# PIC32MK1024GPK100 device description
Architecture: MIPS; Family: PIC32MK; Series: PIC32MK
Registers are 32-bit, read-write, no defined reset value unless marked. A register's access mark holds for its fields unless they carry their own. Offsets are from the block's base; [hi:lo] are bit positions; {n}, {i} and the like mark numbered series.

## CDAC
Instances: CDAC 0x1f820000 in periph_pb2_std
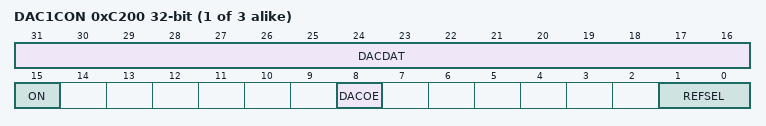
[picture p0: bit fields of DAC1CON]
{0xC000+0x200*i} DAC{i}CON (i=1..3) — CDAC Control Register
  [31:16] DACDAT
  [15] ON — CDAC Enable bit
    1=The CDAC is enabled; 0=The CDAC is disabled
  [8] DACOE — CDAC Output Buffer Enable bit
    1=Output is enabled; CDAC voltage is connected to the pin; 0=Output is disabled; drive to pin is floating
  [1:0] REFSEL — Reference Source Select bits
    3=Positive reference voltage = AVDD; 0=No reference selected (no reference current consumption)

## CTMU
Instances: CTMU 0x1f82d000 in periph_pb2_std
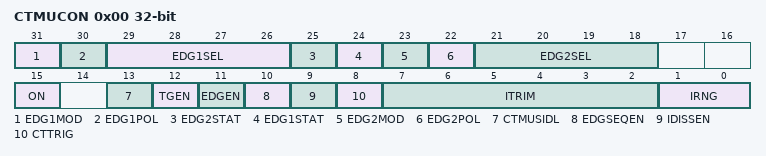
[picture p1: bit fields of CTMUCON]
0x00 CTMUCON — CTMU Control Register
  [31] EDG1MOD — Edge1 Edge Sampling Select bit
    1=Input is edge-sensitive; 0=Input is level-sensitive
  [30] EDG1POL — Edge 1 Polarity Select bit
    1=Edge1 programmed for a high level response; 0=Edge1 programmed for a low level response
  [29:26] EDG1SEL — Edge 1 Source Select bits
    15=C5OUT pin is selected; 14=C4OUT pin is selected; 13=C1OUT pin is selected; {v}=IC{v-6} Capture Event is selected (v=7..12); 6=OC4 Capture Event is selected; 5=OC3 Capture Event is selected; 4=OC2 Capture Event is selected; 3=CTED1 pin is selected; 2=CTED2 pin is selected; 1=OC1 Compare Event is selected; 0=Timer1 Event is selected
  [25] EDG2STAT — Edge2 Status bit
    1=Edge2 event has occurred; 0=Edge2 event has not occurred
  [24] EDG1STAT — Edge1 Status bit
    1=Edge1 event has occurred; 0=Edge1 event has not occurred
  [23] EDG2MOD — Edge2 Edge Sampling Select bit
    1=Input is edge-sensitive; 0=Input is level-sensitive
  [22] EDG2POL — Edge 2 Polarity Select bit
    1=Edge2 programmed for a high level response; 0=Edge2 programmed for a low level response
  [21:18] EDG2SEL — Edge 2 Source Select bits
    15=C5OUT Capture Event is selected; 14=C4OUT pin is selected; 13=C1OUT pin is selected; 12=PBCLK2 is selected; {v}=IC{v-6} Capture Event is selected (v=7..11); 6=OC4 Capture Event is selected; 5=OC3 Capture Event is selected; 4=OC2 Capture Event is selected; 3=CTED1 pin is selected; 2=CTED2 pin is selected; 1=OC1 Compare Event is selected; 0=Timer1 Event is selected
  [15] ON — ON Enable bit
    1=Module is enabled; 0=Module is disabled
  [13] CTMUSIDL — Stop in Idle Mode bit
    1=Discontinue module operation when device enters Idle mode; 0=Continue module operation in Idle mode
  [12] TGEN — Time Generation Enable bit
    1=Enables edge delay generation; 0=Disables edge delay generation
  [11] EDGEN — Edge Enable bit
    1=Edges are not blocked; 0=Edges are blocked
  [10] EDGSEQEN — Edge Sequence Enable bit
    1=Edge1 must occur before Edge2 can occur; 0=No edge sequence is needed
  [9] IDISSEN — Analog Current Source Control bit
    1=Analog current source output is grounded; 0=Analog current source output is not grounded
  [8] CTTRIG — Trigger Control bit
    1=Trigger output is enabled; 0=Trigger output is disabled
  [7:2] ITRIM — Current Source Trim bits
    31=Maximum positive change from nominal current; 1=Minimum positive change from nominal current; 0=Nominal current output specified by IRNG; 63=Minimum negative change from nominal current; 33=Maximum negative change from nominal current
  [1:0] IRNG — Current Range Select bits
    3=100 times base current; 2=10 times base current; 1=Base current level; 0=1000 times base current

## DMT
Instances: DMT 0x1f800000 in periph_pb1_std
0xE00 DMTCON — Deadman Timer Control Register
  [15] ON — Deadman Timer Module Enable bit
    1=Deadman Timer module is enabled; 0=Deadman Timer module is disabled
0xE10 DMTPRECLR — Deadman Timer Preclear Register
  [15:8] STEP1 — Preclear Enable bits
    64=Enables the Deadman Timer Preclear (Step 1)
0xE20 DMTCLR — Deadman Timer Clear Register
  [7:0] STEP2 — Clear Timer bits
    8=Clears STEP1
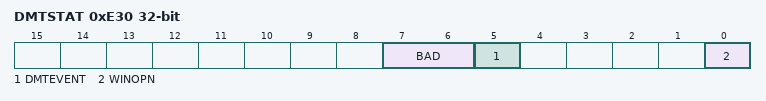
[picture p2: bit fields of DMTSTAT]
0xE30 DMTSTAT ro — Deadman Timer Status Register
  [7:6] BAD — Bad STEP1/STEP2 Value Detect bit
    3=Incorrect STEP2 value was detected / Incorrect STEP1 value was detected; 2=Incorrect STEP2 value was not detected / Incorrect STEP1 value was detected; 1=Incorrect STEP2 value was detected / Incorrect STEP1 value was not detected; 0=Incorrect STEP2 value was not detected / Incorrect STEP1 value was not detected
  [5] DMTEVENT — Deadman Timer Event bit
    1=Deadman timer event was detected (counter expired or bad STEP1 or STEP2 value was entered prior to counter increment); 0=Deadman timer even was not detected
  [0] WINOPN — Deadman Timer Clear Window bit
    1=Deadman timer clear window is open; 0=Deadman timer clear window is not open
0xE40 DMTCNT ro — Deadman Timer Count Register
  [31:0] COUNTER
0xE60 DMTPSCNT ro — Post Status Configure DMT Count Status Register
  [31:0] PSCNT
0xE70 DMTPSINTV ro — Post Status Configure DMT Interval Status Register
  [31:0] PSINTV

## Notices in the file
Copyright (c) 2019 Microchip Technology Inc.
SPDX-License-Identifier: Apache-2.0
Licensed under the Apache License, Version 2.0 (the "License");
you may not use this file except in compliance with the License.
You may obtain a copy of the License at
http://www.apache.org/licenses/LICENSE-2.0
Unless required by applicable law or agreed to in writing, software
distributed under the License is distributed on an "AS IS" BASIS,
WITHOUT WARRANTIES OR CONDITIONS OF ANY KIND, either express or implied.
See the License for the specific language governing permissions and
limitations under the License.
